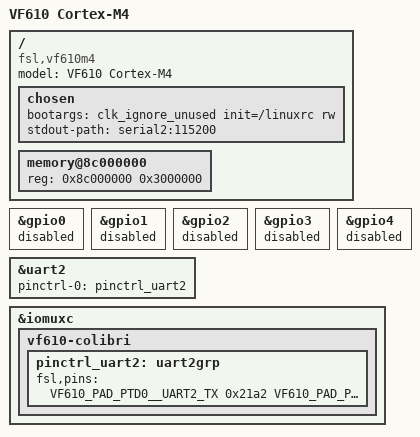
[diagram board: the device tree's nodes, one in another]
/*
 * Device tree for Colibri VF61 Cortex-M4 support
 *
 * Copyright (C) 2015 Stefan Agner
 *
 * This file is dual-licensed: you can use it either under the terms
 * of the GPL or the X11 license, at your option. Note that this dual
 * licensing only applies to this file, and not this project as a
 * whole.
 *
 *  a) This file is free software; you can redistribute it and/or
 *     modify it under the terms of the GNU General Public License as
 *     published by the Free Software Foundation; either version 2 of the
 *     License, or (at your option) any later version.
 *
 *     This file is distributed in the hope that it will be useful,
 *     but WITHOUT ANY WARRANTY; without even the implied warranty of
 *     MERCHANTABILITY or FITNESS FOR A PARTICULAR PURPOSE.  See the
 *     GNU General Public License for more details.
 *
 * Or, alternatively,
 *
 *  b) Permission is hereby granted, free of charge, to any person
 *     obtaining a copy of this software and associated documentation
 *     files (the "Software"), to deal in the Software without
 *     restriction, including without limitation the rights to use,
 *     copy, modify, merge, publish, distribute, sublicense, and/or
 *     sell copies of the Software, and to permit persons to whom the
 *     Software is furnished to do so, subject to the following
 *     conditions:
 *
 *     The above copyright notice and this permission notice shall be
 *     included in all copies or substantial portions of the Software.
 *
 *     THE SOFTWARE IS PROVIDED "AS IS", WITHOUT WARRANTY OF ANY KIND,
 *     EXPRESS OR IMPLIED, INCLUDING BUT NOT LIMITED TO THE WARRANTIES
 *     OF MERCHANTABILITY, FITNESS FOR A PARTICULAR PURPOSE AND
 *     NONINFRINGEMENT. IN NO EVENT SHALL THE AUTHORS OR COPYRIGHT
 *     HOLDERS BE LIABLE FOR ANY CLAIM, DAMAGES OR OTHER LIABILITY,
 *     WHETHER IN AN ACTION OF CONTRACT, TORT OR OTHERWISE, ARISING
 *     FROM, OUT OF OR IN CONNECTION WITH THE SOFTWARE OR THE USE OR
 *     OTHER DEALINGS IN THE SOFTWARE.
 */

/dts-v1/;
#include "vf610m4.dtsi"

/ {
	model = "VF610 Cortex-M4";
	compatible = "fsl,vf610m4";

	chosen {
		bootargs = "clk_ignore_unused init=/linuxrc rw";
		stdout-path = "serial2:115200";
	};

	memory@8c000000 {
		device_type = "memory";
		reg = <0x8c000000 0x3000000>;
	};
};

&gpio0 {
	status = "disabled";
};

&gpio1 {
	status = "disabled";
};

&gpio2 {
	status = "disabled";
};

&gpio3 {
	status = "disabled";
};

&gpio4 {
	status = "disabled";
};

&uart2 {
	pinctrl-names = "default";
	pinctrl-0 = <&pinctrl_uart2>;
	status = "okay";
};

&iomuxc {
	vf610-colibri {
		pinctrl_uart2: uart2grp {
			fsl,pins = <
				VF610_PAD_PTD0__UART2_TX		0x21a2
				VF610_PAD_PTD1__UART2_RX		0x21a1
				VF610_PAD_PTD2__UART2_RTS		0x21a2
				VF610_PAD_PTD3__UART2_CTS		0x21a1
			>;
		};
	};
};
